# cslr_imx_001 register map
Vendor: Texas Instruments
Peripheral module from a debugger description file.
Registers are 32-bit, access not given, reset 0x0 unless marked. A register's access mark holds for its fields unless they carry their own. Offsets are as the file gives them; lines under a group give offsets from that group; [hi:lo] are bit positions; {n}, {i} and the like mark numbered series; 'fields as' and 'values as' point back to an identical list; <NAME> marks a mode.

## IMX — DaVinci - iMX Control Registers
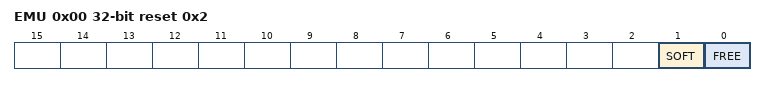
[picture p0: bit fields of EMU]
0x00 EMU reset 0x2 — iMX EMU Register
  [1] SOFT rw — \hSoft Bit. Used in conjunction with FREE bit to determine the emulation mode of iMX. When FREE bit is cleared, SOFT bit selects the mode
    0=WHAT; 1=STOP (iMX stops when the current command completes (fixed))
  [0] FREE rw — \hFree Bit. Used in conjunction with SOFT bit to determine the emulation mode of iMX. When FREE bit is cleared, SOFT bit selects the mode
    0=SOFT (SOFT bit selects the emulation mode.); 1=FREE (iMX runs free regardless of SOFT bit status.)
0x04 START — iMX Start Register
  [15:0] ADDR rw — Writing to this register starts IMX execution from this address in cmdmem
0x08 INTR_EN — iMX INTR Enable Register
  [0] INTREN rw — iMX Interrupt Enable
    0=DISABLE (Disable interrupt); 1=ENABLE (Enable interrupt)
0x0C BUSY — iMX Busy Register
  [0] BUSY ro — iMX Idle/Busy Status
    0=IDLE (iMX idle); 1=BUSY (iMX busy)
0x10 CMDPTR — iMX Command Pointer Register
  [15:0] CMDPTR ro — \hiMX Command Pointer. While in execution or after completion/abortion, shows command pointer value to indicate execution progress
0x14 ABORT — iMX Abort Register
  [0] ABORT rw — \hiMX Abort. Writing 1 to this field aborts iMX execution. Before iMX can be restarted, 0 must be written to this field. Writing 1 while iMX is already idle has no effect.
